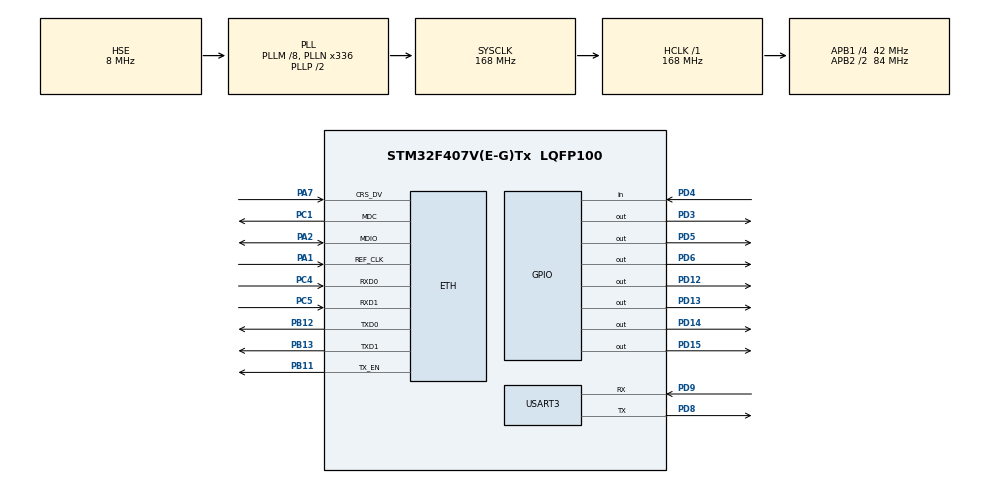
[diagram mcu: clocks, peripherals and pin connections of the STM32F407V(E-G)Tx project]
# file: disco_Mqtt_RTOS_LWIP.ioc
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Mcu.Family=STM32F4
PH0-OSC_IN.Signal=RCC_OSC_IN
RCC.CortexFreq_Value=168000000
PC5.Mode=RMII
PB11.Signal=ETH_TX_EN
PB13.Signal=ETH_TXD1
PD9.Mode=Asynchronous
RCC.SYSCLKSource=RCC_SYSCLKSOURCE_PLLCLK
ProjectManager.StackSize=0x400
LWIP.NETMASK_ADDRESS=255.255.000.000
LWIP.LWIP_HTTPD=1
PD13.Signal=GPIO_Output
RCC.HCLKFreq_Value=168000000
PD4.Signal=GPIO_Input
RCC.APB2TimFreq_Value=168000000
TIM3.Period=999
PD8.Signal=USART3_TX
RCC.AHBFreq_Value=168000000
PH0-OSC_IN.Mode=HSE-External-Oscillator
NVIC.ETH_IRQn=true\:5\:0\:false\:false\:true\:true\:false\:true
RCC.HSE_VALUE=8000000
PC14-OSC32_IN.Mode=LSE-External-Oscillator
TIM3.Prescaler=83
NVIC.TIM2_IRQn=true\:5\:0\:false\:false\:true\:true\:true\:true
VP_FREERTOS_VS_CMSIS_V1.Mode=CMSIS_V1
PH1-OSC_OUT.Mode=HSE-External-Oscillator
Mcu.Package=LQFP100
TIM2.Prescaler=83
PB12.Mode=RMII
NVIC.TimeBase=TIM4_IRQn
PD12.Signal=GPIO_Output
NVIC.TimeBaseIP=TIM4
RCC.APB2CLKDivider=RCC_HCLK_DIV2
RCC.APB1TimFreq_Value=84000000
PC5.Signal=ETH_RXD1
PB13.Mode=RMII
PD6.Signal=GPIO_Output
PD15.Signal=GPIO_Output
VP_TIM3_VS_ClockSourceINT.Mode=Internal
PC4.Mode=RMII
LWIP.IP_ADDRESS=169.254.193.190
RCC.PLLSourceVirtual=RCC_PLLSOURCE_HSE
PC15-OSC32_OUT.Mode=LSE-External-Oscillator
FREERTOS.Tasks01=defaultTask,0,128,StartDefaultTask,Default,NULL,Dynamic,NULL,NULL;DHT22,-3,1024,StartDHT22,Default,NULL,Dynamic,NULL,NULL
PA7.Mode=RMII
PD3.Signal=GPIO_Output
PC4.Signal=ETH_RXD0
ETH.MACAddr=04\:80\:E1\:06\:FD\:EF
PD9.Signal=USART3_RX
PD5.Signal=GPIO_Output
LWIP.LWIP_DHCP=0
RCC.APB1CLKDivider=RCC_HCLK_DIV4
PC14-OSC32_IN.Signal=RCC_OSC32_IN
VP_LWIP_VS_Enabled.Mode=Enabled
LWIP.GATEWAY_ADDRESS=169.254.193.090
PB11.Mode=RMII
ProjectManager.TargetToolchain=TrueSTUDIO
PD8.Mode=Asynchronous
PC15-OSC32_OUT.Signal=RCC_OSC32_OUT
PA1.Signal=ETH_REF_CLK
board=STM32F407G-DISC1
RCC.VCOOutputFreq_Value=336000000
NVIC.TIM3_IRQn=true\:5\:0\:false\:false\:true\:true\:true\:true
RCC.APB2Freq_Value=84000000
PA1.Mode=RMII
VP_TIM2_VS_ClockSourceINT.Mode=Internal
PH1-OSC_OUT.Signal=RCC_OSC_OUT
TIM2.Period=999
Mcu.Name=STM32F407V(E-G)Tx
PA2.Signal=ETH_MDIO
PD14.Signal=GPIO_Output
RCC.48MHZClocksFreq_Value=48000000
RCC.SYSCLKFreq_VALUE=168000000
ETH.MediaInterface=ETH_MEDIA_INTERFACE_RMII
USART3.VirtualMode=VM_ASYNC
ProjectManager.HeapSize=0x200
LWIP.Version=v2.1.2_Cube
VP_SYS_VS_tim4.Mode=TIM4
RCC.HSI_VALUE=16000000
RCC.PLLQ=7
NVIC.PriorityGroup=NVIC_PRIORITYGROUP_4
RCC.PLLM=8
RCC.PLLN=336
PA2.Mode=RMII
NVIC.TIM4_IRQn=true\:0\:0\:false\:false\:true\:false\:false\:true
RCC.APB1Freq_Value=42000000
PC1.Signal=ETH_MDC
PB12.Signal=ETH_TXD0
PC1.Mode=RMII
PA7.Signal=ETH_CRS_DV

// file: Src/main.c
/* USER CODE BEGIN Header */
/**
  ******************************************************************************
  * @file           : main.c
  * @brief          : Main program body
  ******************************************************************************
  * @attention
  *
  * <h2><center>&copy; Copyright (c) 2020 STMicroelectronics.
  * All rights reserved.</center></h2>
  *
  * This software component is licensed by ST under Ultimate Liberty license
  * SLA0044, the "License"; You may not use this file except in compliance with
  * the License. You may obtain a copy of the License at:
  *                             www.st.com/SLA0044
  *
  ******************************************************************************
  */
/* USER CODE END Header */

#include "main.h"
#include "cmsis_os.h"
#include "lwip.h"

/* USER CODE BEGIN Includes */
#include "lwip_mqtt.h"

/* USER CODE END Includes */

TIM_HandleTypeDef htim2;
TIM_HandleTypeDef htim3;

UART_HandleTypeDef huart3;

osThreadId defaultTaskHandle;
osThreadId DHT22Handle;

void SystemClock_Config(void);
static void MX_GPIO_Init(void);
static void MX_TIM2_Init(void);
static void MX_TIM3_Init(void);
static void MX_USART3_UART_Init(void);
void StartDefaultTask(void const * argument);
void StartDHT22(void const * argument);

/* USER CODE BEGIN PFP */
uint32_t count,num=0;
/* USER CODE END PFP */

/* USER CODE BEGIN 0 */
char pacote[1000];
mqtt_client_t *client;

/* USER CODE END 0 */

int main(void)
{

  /* MCU Configuration--------------------------------------------------------*/

  /* Reset of all peripherals, Initializes the Flash interface and the Systick. */
  HAL_Init();

  /* Configure the system clock */
  SystemClock_Config();

  /* Initialize all configured peripherals */
  MX_GPIO_Init();
  MX_TIM2_Init();
  MX_TIM3_Init();
  MX_USART3_UART_Init();

  /* Create the thread(s) */
  /* definition and creation of defaultTask */
  osThreadDef(defaultTask, StartDefaultTask, osPriorityNormal, 0, (3*1024));
  defaultTaskHandle = osThreadCreate(osThread(defaultTask), NULL);

  /* definition and creation of DHT22 */
  osThreadDef(DHT22, StartDHT22, osPriorityIdle, 0, 128);
  DHT22Handle = osThreadCreate(osThread(DHT22), NULL);

  /* Start scheduler */
  osKernelStart();

  /* We should never get here as control is now taken by the scheduler */
  /* Infinite loop */
  while (1)
  {

  }
}

void SystemClock_Config(void)
{
  RCC_OscInitTypeDef RCC_OscInitStruct = {0};
  RCC_ClkInitTypeDef RCC_ClkInitStruct = {0};

  /** Configure the main internal regulator output voltage
  */
  __HAL_RCC_PWR_CLK_ENABLE();
  __HAL_PWR_VOLTAGESCALING_CONFIG(PWR_REGULATOR_VOLTAGE_SCALE1);
  /** Initializes the CPU, AHB and APB busses clocks
  */
  RCC_OscInitStruct.OscillatorType = RCC_OSCILLATORTYPE_HSE;
  RCC_OscInitStruct.HSEState = RCC_HSE_ON;
  RCC_OscInitStruct.PLL.PLLState = RCC_PLL_ON;
  RCC_OscInitStruct.PLL.PLLSource = RCC_PLLSOURCE_HSE;
  RCC_OscInitStruct.PLL.PLLM = 8;
  RCC_OscInitStruct.PLL.PLLN = 336;
  RCC_OscInitStruct.PLL.PLLP = RCC_PLLP_DIV2;
  RCC_OscInitStruct.PLL.PLLQ = 7;
  if (HAL_RCC_OscConfig(&RCC_OscInitStruct) != HAL_OK)
  {
    Error_Handler();
  }
  /** Initializes the CPU, AHB and APB busses clocks
  */
  RCC_ClkInitStruct.ClockType = RCC_CLOCKTYPE_HCLK|RCC_CLOCKTYPE_SYSCLK
                              |RCC_CLOCKTYPE_PCLK1|RCC_CLOCKTYPE_PCLK2;
  RCC_ClkInitStruct.SYSCLKSource = RCC_SYSCLKSOURCE_PLLCLK;
  RCC_ClkInitStruct.AHBCLKDivider = RCC_SYSCLK_DIV1;
  RCC_ClkInitStruct.APB1CLKDivider = RCC_HCLK_DIV4;
  RCC_ClkInitStruct.APB2CLKDivider = RCC_HCLK_DIV2;

  if (HAL_RCC_ClockConfig(&RCC_ClkInitStruct, FLASH_LATENCY_5) != HAL_OK)
  {
    Error_Handler();
  }
}

static void MX_TIM2_Init(void)
{

  TIM_ClockConfigTypeDef sClockSourceConfig = {0};
  TIM_MasterConfigTypeDef sMasterConfig = {0};

  htim2.Instance = TIM2;
  htim2.Init.Prescaler = 83;
  htim2.Init.CounterMode = TIM_COUNTERMODE_UP;
  htim2.Init.Period = 999;
  htim2.Init.ClockDivision = TIM_CLOCKDIVISION_DIV1;
  htim2.Init.AutoReloadPreload = TIM_AUTORELOAD_PRELOAD_DISABLE;
  if (HAL_TIM_Base_Init(&htim2) != HAL_OK)
  {
    Error_Handler();
  }
  sClockSourceConfig.ClockSource = TIM_CLOCKSOURCE_INTERNAL;
  if (HAL_TIM_ConfigClockSource(&htim2, &sClockSourceConfig) != HAL_OK)
  {
    Error_Handler();
  }
  sMasterConfig.MasterOutputTrigger = TIM_TRGO_RESET;
  sMasterConfig.MasterSlaveMode = TIM_MASTERSLAVEMODE_DISABLE;
  if (HAL_TIMEx_MasterConfigSynchronization(&htim2, &sMasterConfig) != HAL_OK)
  {
    Error_Handler();
  }

}

static void MX_TIM3_Init(void)
{

  TIM_ClockConfigTypeDef sClockSourceConfig = {0};
  TIM_MasterConfigTypeDef sMasterConfig = {0};

  htim3.Instance = TIM3;
  htim3.Init.Prescaler = 83;
  htim3.Init.CounterMode = TIM_COUNTERMODE_UP;
  htim3.Init.Period = 999;
  htim3.Init.ClockDivision = TIM_CLOCKDIVISION_DIV1;
  htim3.Init.AutoReloadPreload = TIM_AUTORELOAD_PRELOAD_DISABLE;
  if (HAL_TIM_Base_Init(&htim3) != HAL_OK)
  {
    Error_Handler();
  }
  sClockSourceConfig.ClockSource = TIM_CLOCKSOURCE_INTERNAL;
  if (HAL_TIM_ConfigClockSource(&htim3, &sClockSourceConfig) != HAL_OK)
  {
    Error_Handler();
  }
  sMasterConfig.MasterOutputTrigger = TIM_TRGO_RESET;
  sMasterConfig.MasterSlaveMode = TIM_MASTERSLAVEMODE_DISABLE;
  if (HAL_TIMEx_MasterConfigSynchronization(&htim3, &sMasterConfig) != HAL_OK)
  {
    Error_Handler();
  }

}

static void MX_USART3_UART_Init(void)
{

  huart3.Instance = USART3;
  huart3.Init.BaudRate = 115200;
  huart3.Init.WordLength = UART_WORDLENGTH_8B;
  huart3.Init.StopBits = UART_STOPBITS_1;
  huart3.Init.Parity = UART_PARITY_NONE;
  huart3.Init.Mode = UART_MODE_TX_RX;
  huart3.Init.HwFlowCtl = UART_HWCONTROL_NONE;
  huart3.Init.OverSampling = UART_OVERSAMPLING_16;
  if (HAL_UART_Init(&huart3) != HAL_OK)
  {
    Error_Handler();
  }

}

static void MX_GPIO_Init(void)
{
  GPIO_InitTypeDef GPIO_InitStruct = {0};

  /* GPIO Ports Clock Enable */
  __HAL_RCC_GPIOC_CLK_ENABLE();
  __HAL_RCC_GPIOH_CLK_ENABLE();
  __HAL_RCC_GPIOA_CLK_ENABLE();
  __HAL_RCC_GPIOB_CLK_ENABLE();
  __HAL_RCC_GPIOD_CLK_ENABLE();

  /*Configure GPIO pin Output Level */
  HAL_GPIO_WritePin(GPIOD, GPIO_PIN_12|GPIO_PIN_13|GPIO_PIN_14|GPIO_PIN_15
                          |GPIO_PIN_3|GPIO_PIN_5|GPIO_PIN_6, GPIO_PIN_RESET);

  /*Configure GPIO pins : PD12 PD13 PD14 PD15
                           PD3 PD5 PD6 */
  GPIO_InitStruct.Pin = GPIO_PIN_12|GPIO_PIN_13|GPIO_PIN_14|GPIO_PIN_15
                          |GPIO_PIN_3|GPIO_PIN_5|GPIO_PIN_6;
  GPIO_InitStruct.Mode = GPIO_MODE_OUTPUT_PP;
  GPIO_InitStruct.Pull = GPIO_NOPULL;
  GPIO_InitStruct.Speed = GPIO_SPEED_FREQ_LOW;
  HAL_GPIO_Init(GPIOD, &GPIO_InitStruct);

  /*Configure GPIO pin : PD4 */
  GPIO_InitStruct.Pin = GPIO_PIN_4;
  GPIO_InitStruct.Mode = GPIO_MODE_INPUT;
  GPIO_InitStruct.Pull = GPIO_NOPULL;
  HAL_GPIO_Init(GPIOD, &GPIO_InitStruct);

}

void StartDefaultTask(void const * argument)
{
  /* init code for LWIP */
  MX_LWIP_Init();
 client = mqtt_client_new();
if(client != NULL) {
   sprintf(pacote,"hello_mohamed");
    example_do_connect(client, "hello_world");
    example_publish(client, pacote);
}
  if(HAL_TIM_Base_Init(&htim2) != HAL_OK)
  {
    /* Initialization Error */
    Error_Handler();
  }

  /*##-2- Start the TIM Base generation in interrupt mode ####################*/
  /* Start Channel1 */
  if(HAL_TIM_Base_Start_IT(&htim2) != HAL_OK)
  {
    /* Starting Error */
    Error_Handler();
  }
  for(;;)
  {
    osDelay(1);
  }
}

void StartDHT22(void const * argument)
{
  for(;;)
  {
    osDelay(1);
  }
}

 /**
  * @brief  Period elapsed callback in non blocking mode
  * @note   This function is called  when TIM4 interrupt took place, inside
  * HAL_TIM_IRQHandler(). It makes a direct call to HAL_IncTick() to increment
  * a global variable "uwTick" used as application time base.
  * @param  htim : TIM handle
  * @retval None
  */
void HAL_TIM_PeriodElapsedCallback(TIM_HandleTypeDef *htim)
{
  if (htim->Instance == TIM4) {
    HAL_IncTick();
  }
  if (htim->Instance == TIM2) {
	  count++;
	  if(count>199){
		  count=0;
	  if(client != NULL) {
		num++;
	sprintf(pacote,"hello Timer:%d",num);
	    example_do_connect(client, "hello_world");
	    example_publish(client, pacote);
	  }
  }
  }
}

void Error_Handler(void)
{
}

/************************ (C) COPYRIGHT STMicroelectronics *****END OF FILE****/
